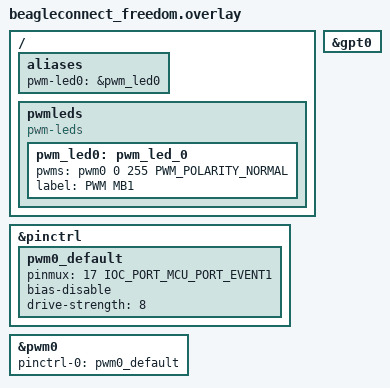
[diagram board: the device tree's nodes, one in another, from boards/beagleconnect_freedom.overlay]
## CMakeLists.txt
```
# SPDX-License-Identifier: Apache-2.0

cmake_minimum_required(VERSION 3.28.0)
find_package(Zephyr REQUIRED HINTS $ENV{ZEPHYR_BASE})
project(blinky_pwm)

target_sources(app PRIVATE src/main.c)
```

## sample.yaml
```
sample:
  name: Blink LED (PWM based)
tests:
  sample.basic.blink_led:
    filter: dt_alias_exists("pwm-led0") and dt_compat_enabled("pwm-leds")
    integration_platforms:
      - esp32c3_devkitc
    tags:
      - drivers
      - pwm
    depends_on: pwm
    harness: console
    harness_config:
      type: multi_line
      ordered: true
      regex:
        - "PWM-based blinky"
        - "Calibrating for channel [0-9]+"
        - "Done calibrating; maximum/minimum periods [0-9]+/[0-9]+ nsec"
        - "Using period [0-9]+"
        - "Using period [0-9]+"
```

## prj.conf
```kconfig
CONFIG_STDOUT_CONSOLE=y
CONFIG_PRINTK=y
CONFIG_PWM=y
CONFIG_LOG=y
CONFIG_LOG_PRINTK=y
CONFIG_LOG_MODE_IMMEDIATE=y
CONFIG_PWM_LOG_LEVEL_DBG=y
```

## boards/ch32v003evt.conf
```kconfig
CONFIG_LOG_MODE_MINIMAL=y
CONFIG_CBPRINTF_NANO=y
```

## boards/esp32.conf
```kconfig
CONFIG_LED=y
CONFIG_PWM_LED_ESP32=y
```

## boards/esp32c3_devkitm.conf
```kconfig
CONFIG_LED=y
CONFIG_LED_PWM=y
CONFIG_PWM_LED_ESP32=y
```

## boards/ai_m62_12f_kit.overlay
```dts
/*
 * Copyright (c) 2025 MASSDRIVER EI (massdriver.space)
 *
 * SPDX-License-Identifier: Apache-2.0
 */

/ {
	leds {
		status = "disabled";
	};
};

&pwmleds {
	status = "okay";
};

&pwm0 {
	pinctrl-0 = <&white_pwm_pinctrl>;
	pinctrl-names = "default";
	status = "okay";
};
```

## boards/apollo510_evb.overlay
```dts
/*
 * Copyright (c) 2025 Ambiq
 *
 * SPDX-License-Identifier: Apache-2.0
 */

&pwmleds {
	status = "okay";
};

&pwm2 {
	status = "okay";
};
```

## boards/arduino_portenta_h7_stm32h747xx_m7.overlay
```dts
/*
 * Copyright (c) 2024 Arduino SA
 *
 * SPDX-License-Identifier: Apache-2.0
 */

&timers3 {
	status = "okay";
	st,prescaler = <1000>;

	pwm3: pwm {
		status = "okay";
		pinctrl-0 = <&tim3_ch1_pc6 &tim3_ch2_pc7>;
		pinctrl-names = "default";
	};
};

/ {
	aliases {
		pwm-led0 = &pwm_led0;
	};

	pwmleds {
		compatible = "pwm-leds";
		pwm_led0: pwm_led_0 {
			pwms = <&pwm3 2 PWM_HZ(1000) PWM_POLARITY_NORMAL>;
        	label = "PWM LED Arduino PIN D4";
		};
	};
};
```

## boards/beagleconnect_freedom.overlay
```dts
/*
 * Copyright (c) 2024 Ayush Singh <ayush@beagleboard.org>
 *
 * SPDX-License-Identifier: Apache-2.0
 */

/ {
	aliases {
		pwm-led0 = &pwm_led0;
	};

	pwmleds {
		compatible = "pwm-leds";
		pwm_led0: pwm_led_0 {
			pwms = <&pwm0 0 255 PWM_POLARITY_NORMAL>;
			label = "PWM MB1";
		};
	};
};

&pinctrl {
	pwm0_default: pwm0_default {
		pinmux = <17 IOC_PORT_MCU_PORT_EVENT1>;
		bias-disable;
		drive-strength = <8>;
	};
};

&gpt0 {
	status = "okay";
};

&pwm0 {
	status = "okay";
	pinctrl-0 = <&pwm0_default>;
	pinctrl-names = "default";
};
```

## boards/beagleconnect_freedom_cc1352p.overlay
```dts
/*
 * Copyright (c) 2024 Ayush Singh <ayush@beagleboard.org>
 *
 * SPDX-License-Identifier: Apache-2.0
 */

/ {
	aliases {
		pwm-led0 = &pwm_led0;
	};

	pwmleds {
		compatible = "pwm-leds";

		pwm_led0: pwm_led_0 {
			pwms = <&pwm0 0 255 PWM_POLARITY_NORMAL>;
			label = "PWM MB1";
		};
	};
};
```

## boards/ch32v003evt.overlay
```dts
/*
 * Copyright (c) 2025 Michael Hope <michaelh@juju.nz>
 *
 * SPDX-License-Identifier: Apache-2.0
 */

/ {
	leds {
		status = "disabled";
	};
};

&pwmleds {
	status = "okay";
};

&tim2 {
	/*
	 * The sample runs from 1 Hz to 128 Hz, ceil(48 MHz / 65536 / 1 Hz)
	 * is 733, and the prescaler property is one less than that.
	 */
	prescaler = <732>;
	status = "okay";
};

&pwm2 {
	pinctrl-0 = <&red_pwm_pinctrl>;
	pinctrl-names = "default";
	status = "okay";
};
```

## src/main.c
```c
/*
 * Copyright (c) 2016 Intel Corporation
 * Copyright (c) 2020 Nordic Semiconductor ASA
 *
 * SPDX-License-Identifier: Apache-2.0
 */

/**
 * @file Sample app to demonstrate PWM.
 */

#include <zephyr/kernel.h>
#include <zephyr/sys/printk.h>
#include <zephyr/device.h>
#include <zephyr/drivers/pwm.h>

static const struct pwm_dt_spec pwm_led0 = PWM_DT_SPEC_GET(DT_ALIAS(pwm_led0));

#define MIN_PERIOD PWM_SEC(1U) / 128U
#define MAX_PERIOD PWM_SEC(1U)

int main(void)
{
	uint32_t max_period;
	uint32_t period;
	uint8_t dir = 0U;
	int ret;

	printk("PWM-based blinky\n");

	if (!pwm_is_ready_dt(&pwm_led0)) {
		printk("Error: PWM device %s is not ready\n",
		       pwm_led0.dev->name);
		return 0;
	}

	/*
	 * In case the default MAX_PERIOD value cannot be set for
	 * some PWM hardware, decrease its value until it can.
	 *
	 * Keep its value at least MIN_PERIOD * 4 to make sure
	 * the sample changes frequency at least once.
	 */
	printk("Calibrating for channel %d...\n", pwm_led0.channel);
	max_period = MAX_PERIOD;
	while (pwm_set_dt(&pwm_led0, max_period, max_period / 2U)) {
		max_period /= 2U;
		if (max_period < (4U * MIN_PERIOD)) {
			printk("Error: PWM device "
			       "does not support a period at least %lu\n",
			       4U * MIN_PERIOD);
			return 0;
		}
	}

	printk("Done calibrating; maximum/minimum periods %u/%lu nsec\n",
	       max_period, MIN_PERIOD);

	period = max_period;
	while (1) {
		ret = pwm_set_dt(&pwm_led0, period, period / 2U);
		if (ret) {
			printk("Error %d: failed to set pulse width\n", ret);
			return 0;
		}
		printk("Using period %d\n", period);

		period = dir ? (period * 2U) : (period / 2U);
		if (period > max_period) {
			period = max_period / 2U;
			dir = 0U;
		} else if (period < MIN_PERIOD) {
			period = MIN_PERIOD * 2U;
			dir = 1U;
		}

		k_sleep(K_SECONDS(4U));
	}
	return 0;
}
```
